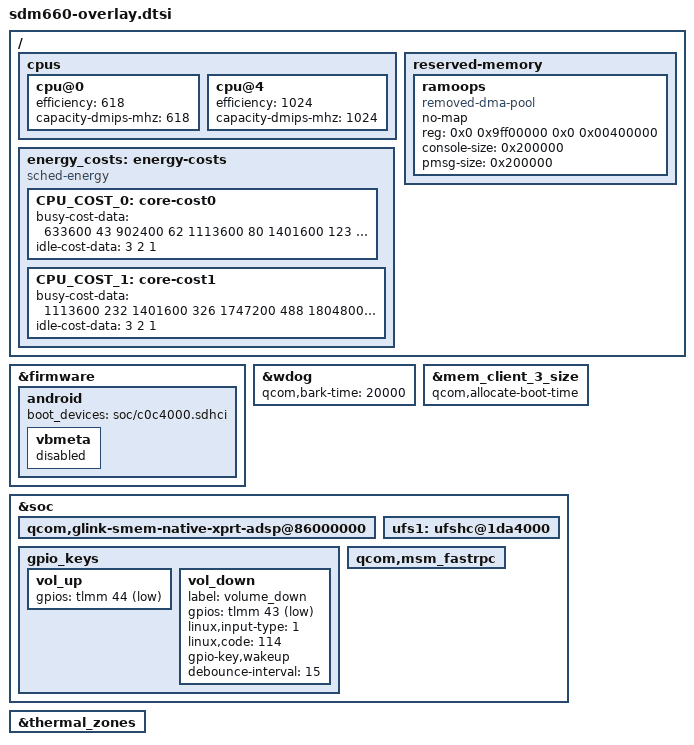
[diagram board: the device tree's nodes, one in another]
/* Copyright (c) 2016-2019, The Linux Foundation. All rights reserved.
 *
 * This program is free software; you can redistribute it and/or modify
 * it under the terms of the GNU General Public License version 2 and
 * only version 2 as published by the Free Software Foundation.
 *
 * This program is distributed in the hope that it will be useful,
 * but WITHOUT ANY WARRANTY; without even the implied warranty of
 * MERCHANTABILITY or FITNESS FOR A PARTICULAR PURPOSE.  See the
 * GNU General Public License for more details.
 */

/ {
cpus {
	cpu@0 {
		efficiency = <618>;
		capacity-dmips-mhz = <618>;
	};

	cpu@4 {
		efficiency = <1024>;
		capacity-dmips-mhz = <1024>;
	};
};

energy_costs: energy-costs {
	compatible = "sched-energy";

	CPU_COST_0: core-cost0 {
		busy-cost-data = <
			  633600   43
			  902400   62
			 1113600   80
			 1401600  123
			 1536000  144
			 1612800  160
		>;
		idle-cost-data = <
			3 2 1
		>;
	};

	CPU_COST_1: core-cost1 {
		busy-cost-data = <
			 1113600  232
			 1401600  326
			 1747200  488
			 1804800  510
		>;
		idle-cost-data = <
			3 2 1
		>;
	};
};

	reserved-memory {
		ramoops {
			compatible = "removed-dma-pool", "ramoops";
			no-map;
			reg = <0x0 0x9ff00000 0x0 0x00400000>;
			console-size = <0x200000>;
			pmsg-size = <0x200000>;
			status = "ok";
		};
	};
};

&firmware {
	android {
		boot_devices = "soc/c0c4000.sdhci";
		/delete-node/ fstab;

		vbmeta {
			status = "disabled";
		};
	};
};

&wdog {
	qcom,bark-time = <20000>;

};

&mem_client_3_size {
	/delete-property/ qcom,allocate-on-request;
	qcom,allocate-boot-time;
};

&soc {
	qcom,glink-smem-native-xprt-adsp@86000000 {
		/delete-property/ cpu-affinity;
	};
	
	ufs1: ufshc@1da4000 {
		/delete-property/ pinctrl-names;
		/delete-property/ pinctrl-0;
		/delete-property/ pinctrl-1;
	};

	gpio_keys {
		/delete-node/ camera_focus;
		/delete-node/ camera_snapshot;

		vol_up {
			gpios = <&tlmm 44 0x1>;
		};

		vol_down {
			label = "volume_down";
			gpios = <&tlmm 43 0x1>;
			linux,input-type = <1>;
			linux,code = <114>;
			gpio-key,wakeup;
			debounce-interval = <15>;
		};
	};

	qcom,msm_fastrpc {
		/delete-property/ qcom,fastrpc-adsp-sensors-pdr;
	};
};

&thermal_zones {
	/delete-node/ vbat_adc;
	/delete-node/ vbat_low;
	/delete-node/ vbat_too_low;
};
